AUTOSAR XML (schema 314)
package /ComponentType
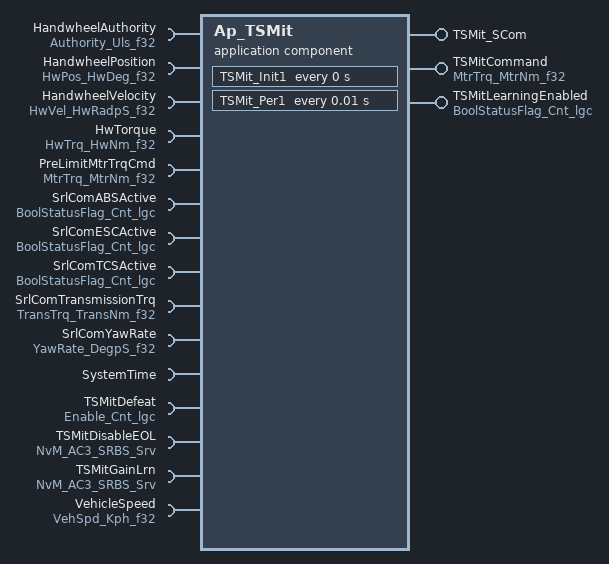
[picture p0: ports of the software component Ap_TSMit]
  application software component type Ap_TSMit
    provide port TSMit_SCom: provided-interface=TSMit_SCom
      provided-com-specs:
        operation=GainReset, queue-length=1
        operation=GetFcnDefeat, queue-length=1
        operation=GetLongTermGains, queue-length=1
        operation=GetLrnDefeat, queue-length=1
        operation=SetFcnDefeat, queue-length=1
        operation=SetLongTermGains, queue-length=1
        operation=SetLrnDefeat, queue-length=1
    provide port TSMitCommand: unqueued-sender-com-spec{data-element=MtrNm_f32, can-invalidate=false, init-value=D_ZERO_ULS_F32}, provided-interface=MtrTrq_MtrNm_f32
    provide port TSMitLearningEnabled: unqueued-sender-com-spec{data-element=Cnt_lgc, can-invalidate=false, init-value=D_FALSE_CNT_LGC}, provided-interface=BoolStatusFlag_Cnt_lgc
    15 x require port:
      HandwheelAuthority: unqueued-receiver-com-spec{data-element=Uls_f32, init-value=D_ZERO_ULS_F32}, required-interface=Authority_Uls_f32
      HandwheelPosition: unqueued-receiver-com-spec{data-element=HwDeg_f32, init-value=D_ZERO_ULS_F32}, required-interface=HwPos_HwDeg_f32
      HandwheelVelocity: unqueued-receiver-com-spec{data-element=HwRadpS_f32, init-value=D_ZERO_ULS_F32}, required-interface=HwVel_HwRadpS_f32
      HwTorque: unqueued-receiver-com-spec{data-element=HwNm_f32, init-value=D_ZERO_ULS_F32}, required-interface=HwTrq_HwNm_f32
      PreLimitMtrTrqCmd: unqueued-receiver-com-spec{data-element=MtrNm_f32, init-value=D_ZERO_ULS_F32}, required-interface=MtrTrq_MtrNm_f32
      SrlComABSActive: unqueued-receiver-com-spec{data-element=Cnt_lgc, init-value=D_FALSE_CNT_LGC}, required-interface=BoolStatusFlag_Cnt_lgc
      SrlComESCActive: unqueued-receiver-com-spec{data-element=Cnt_lgc, init-value=D_FALSE_CNT_LGC}, required-interface=BoolStatusFlag_Cnt_lgc
      SrlComTCSActive: unqueued-receiver-com-spec{data-element=Cnt_lgc, init-value=D_FALSE_CNT_LGC}, required-interface=BoolStatusFlag_Cnt_lgc
      SrlComTransmissionTrq: unqueued-receiver-com-spec{data-element=TransNm_f32, init-value=D_ZERO_ULS_F32}, required-interface=TransTrq_TransNm_f32
      SrlComYawRate: unqueued-receiver-com-spec{data-element=DegpS_f32, init-value=D_ZERO_ULS_F32}, required-interface=YawRate_DegpS_f32
      SystemTime: required-interface=SystemTime
        required-com-specs:
          DtrmnElapsedTime_mS_u16
          DtrmnElapsedTime_mS_u32
          DtrmnElapsedTime_uS_u16
          DtrmnElapsedTime_uS_u32
          GetSystemTime_mS_u32
          GetSystemTime_uS_u32
      TSMitDefeat: unqueued-receiver-com-spec{data-element=Cnt_lgc, init-value=D_FALSE_CNT_LGC}, required-interface=Enable_Cnt_lgc
      TSMitDisableEOL: required-com-specs=[EraseBlock, GetErrorStatus, InvalidateNvBlock, ReadBlock, SetRamBlockStatus, WriteBlock], required-interface=NvM_AC3_SRBS_Srv
      TSMitGainLrn: required-com-specs=[EraseBlock, GetErrorStatus, InvalidateNvBlock, ReadBlock, SetRamBlockStatus, WriteBlock], required-interface=NvM_AC3_SRBS_Srv
      VehicleSpeed: unqueued-receiver-com-spec{data-element=Kph_f32, init-value=D_ZERO_ULS_F32}, required-interface=VehSpd_Kph_f32
  internal behavior Ap_TSMit_InternalBehavior: component=Ap_TSMit
    timing event TSMit_Init1_InitEvent: start-on-event=TSMit_Init1, period=0
    timing event TMT_TSMit_Per1: start-on-event=TSMit_Per1, period=0.01
    7 x operation invoked event:
      OIT_TSMit_SCom_GainReset_TSMit_SCom_GainReset: start-on-event=TSMit_SCom_GainReset, operation=TSMit_SCom.GainReset
      OIT_TSMit_SCom_GetFcnDefeat_TSMit_SCom_GetFcnDefeat: start-on-event=TSMit_SCom_GetFcnDefeat, operation=TSMit_SCom.GetFcnDefeat
      OIT_TSMit_SCom_GetLongTermGains_TSMit_SCom_GetLongTermGains: start-on-event=TSMit_SCom_GetLongTermGains, operation=TSMit_SCom.GetLongTermGains
      OIT_TSMit_SCom_GetLrnDefeat_TSMit_SCom_GetLrnDefeat: start-on-event=TSMit_SCom_GetLrnDefeat, operation=TSMit_SCom.GetLrnDefeat
      OIT_TSMit_SCom_SetFcnDefeat_TSMit_SCom_SetFcnDefeat: start-on-event=TSMit_SCom_SetFcnDefeat, operation=TSMit_SCom.SetFcnDefeat
      OIT_TSMit_SCom_SetLongTermGains_TSMit_SCom_SetLongTermGains: start-on-event=TSMit_SCom_SetLongTermGains, operation=TSMit_SCom.SetLongTermGains
      OIT_TSMit_SCom_SetLrnDefeat_TSMit_SCom_SetLrnDefeat: start-on-event=TSMit_SCom_SetLrnDefeat, operation=TSMit_SCom.SetLrnDefeat
    per instance memory TSMitDisableEOL: type=TSMit_Disable_Type, type-definition=/DataType/TSMit_Disable_Type
    per instance memory TSMitGainLrn: type=TSMit_Gain_Type, type-definition=/DataType/TSMit_Gain_Type
    port-api-options:
      enable-take-address=false, indirect-api=false, port=HandwheelAuthority
      enable-take-address=false, indirect-api=false, port=HandwheelPosition
      enable-take-address=false, indirect-api=false, port=HandwheelVelocity
      enable-take-address=false, indirect-api=false, port=HwTorque
      enable-take-address=false, indirect-api=false, port=PreLimitMtrTrqCmd
      enable-take-address=false, indirect-api=false, port=SrlComABSActive
      enable-take-address=false, indirect-api=false, port=SrlComESCActive
      enable-take-address=false, indirect-api=false, port=SrlComTCSActive
      enable-take-address=false, indirect-api=false, port=SrlComTransmissionTrq
      enable-take-address=false, indirect-api=false, port=SrlComYawRate
      enable-take-address=false, indirect-api=false, port=SystemTime
      enable-take-address=false, indirect-api=false, port=TSMit_SCom
      enable-take-address=false, indirect-api=false, port=TSMitCommand
      enable-take-address=false, indirect-api=false, port=TSMitDefeat
      enable-take-address=false, indirect-api=false, port=TSMitDisableEOL
      enable-take-address=false, indirect-api=false, port=TSMitGainLrn
      enable-take-address=false, indirect-api=false, port=TSMitLearningEnabled
      enable-take-address=false, indirect-api=false, port=VehicleSpeed
    9 x runnable:
      TSMit_Init1
        sync call SC_SystemTime_GetSystemTime_mS_u32: operation=SystemTime.GetSystemTime_mS_u32, timeout=0
        sync call SC_TSMitGainLrn_SetRamBlockStatus: operation=TSMitGainLrn.SetRamBlockStatus, timeout=0
      TSMit_Per1
        12 x data read access:
          READ_HandwheelAuthority_Uls_f32: data-element=HandwheelAuthority.Uls_f32
          READ_HandwheelPosition_HwDeg_f32: data-element=HandwheelPosition.HwDeg_f32
          READ_HandwheelVelocity_HwRadpS_f32: data-element=HandwheelVelocity.HwRadpS_f32
          READ_HwTorque_HwNm_f32: data-element=HwTorque.HwNm_f32
          READ_PreLimitMtrTrqCmd_MtrNm_f32: data-element=PreLimitMtrTrqCmd.MtrNm_f32
          READ_SrlComABSActive_Cnt_lgc: data-element=SrlComABSActive.Cnt_lgc
          READ_SrlComESCActive_Cnt_lgc: data-element=SrlComESCActive.Cnt_lgc
          READ_SrlComTCSActive_Cnt_lgc: data-element=SrlComTCSActive.Cnt_lgc
          READ_SrlComTransmissionTrq_TransNm_f32: data-element=SrlComTransmissionTrq.TransNm_f32
          READ_SrlComYawRate_DegpS_f32: data-element=SrlComYawRate.DegpS_f32
          READ_TSMitDefeat_Cnt_lgc: data-element=TSMitDefeat.Cnt_lgc
          READ_VehicleSpeed_Kph_f32: data-element=VehicleSpeed.Kph_f32
        data write access WRITE_TSMitCommand_MtrNm_f32: data-element=TSMitCommand.MtrNm_f32
        data write access WRITE_TSMitLearningEnabled_Cnt_lgc: data-element=TSMitLearningEnabled.Cnt_lgc
        sync call SC_SystemTime_DtrmnElapsedTime_mS_u16: operation=SystemTime.DtrmnElapsedTime_mS_u16, timeout=0
        sync call SC_SystemTime_GetSystemTime_mS_u32: operation=SystemTime.GetSystemTime_mS_u32, timeout=0
      TSMit_SCom_GainReset
        sync call SC_TSMitGainLrn_WriteBlock: operation=TSMitGainLrn.WriteBlock, timeout=0
      TSMit_SCom_GetFcnDefeat
      TSMit_SCom_GetLongTermGains
      TSMit_SCom_GetLrnDefeat
      TSMit_SCom_SetFcnDefeat
        sync call SC_TSMitDisableEOL_WriteBlock: operation=TSMitDisableEOL.WriteBlock, timeout=0
      TSMit_SCom_SetLongTermGains
        sync call SC_TSMitGainLrn_WriteBlock: operation=TSMitGainLrn.WriteBlock, timeout=0
      TSMit_SCom_SetLrnDefeat
        sync call SC_TSMitDisableEOL_WriteBlock: operation=TSMitDisableEOL.WriteBlock, timeout=0
    service-needss:
      swc nv block needs TSMit_Gain_Block: n-data-sets=0, readonly=false, reliability=LOW, resistant-to-changed-sw=false, restore-at-start=false, write-only-once=false, writing-frequency=0, writing-priority=LOW, mirror-block=TSMitGainLrn
      swc nv block needs TSMit_Enable_Block: n-data-sets=0, readonly=false, reliability=LOW, resistant-to-changed-sw=false, restore-at-start=false, write-only-once=false, writing-frequency=0, writing-priority=LOW, mirror-block=TSMitDisableEOL
  swc implementation Ap_TSMit_Implementation: behavior=Ap_TSMit_InternalBehavior
    code-descriptors:
      code Code: type=SRC
